# STM32F446 register map
File version: 1.1
CPU: CM4 r1p0, little endian, no MPU, no FPU, 4 interrupt priority bits
Registers are 32-bit, read-write, reset 0x0 unless marked. A register's access mark holds for its fields unless they carry their own. Offsets are from the block's base; [hi:lo] are bit positions; {n}, {i} and the like mark numbered series; 'fields as' and 'values as' point back to an identical list.

## OTG_FS_GLOBAL — USB on the go full speed
Base 0x50000000
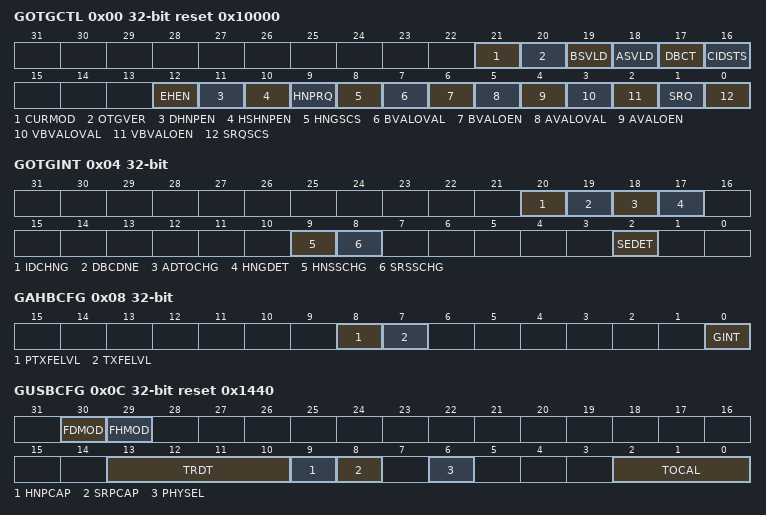
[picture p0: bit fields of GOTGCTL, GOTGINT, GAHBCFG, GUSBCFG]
0x00 GOTGCTL access per field reset 0x10000 — OTG control and status register (OTG_GOTGCTL)
  [21] CURMOD ro — Current mode of operation
  [20] OTGVER rw — OTG version
  [19] BSVLD ro — B-session valid
  [18] ASVLD ro — A-session valid
  [17] DBCT ro — Long/short debounce time
  [16] CIDSTS ro — Connector ID status
  [12] EHEN rw — Embedded host enable
  [11] DHNPEN rw — Device HNP enabled
  [10] HSHNPEN rw — Host set HNP enable
  [9] HNPRQ rw — HNP request
  [8] HNGSCS ro — Host negotiation success
  [7] BVALOVAL rw — B-peripheral session valid override value
  [6] BVALOEN rw — B-peripheral session valid override enable
  [5] AVALOVAL rw — A-peripheral session valid override value
  [4] AVALOEN rw — A-peripheral session valid override enable
  [3] VBVALOVAL rw — Vbus valid override value
  [2] VBVALOEN rw — Vbus valid override enable
  [1] SRQ rw — Session request
  [0] SRQSCS ro — Session request success
0x04 GOTGINT — OTG interrupt register (OTG_GOTGINT)
  [20] IDCHNG
  [19] DBCDNE — Debounce done
  [18] ADTOCHG — A-device timeout change
  [17] HNGDET — Host negotiation detected
  [9] HNSSCHG — Host negotiation success status change
  [8] SRSSCHG — Session request success status change
  [2] SEDET — Session end detected
0x08 GAHBCFG — OTG AHB configuration register (OTG_GAHBCFG)
  [8] PTXFELVL — Periodic TxFIFO empty level
  [7] TXFELVL — TxFIFO empty level
  [0] GINT — Global interrupt mask
0x0C GUSBCFG access per field reset 0x1440 — OTG USB configuration register (OTG_GUSBCFG)
  [30] FDMOD rw — Force device mode
  [29] FHMOD rw — Force host mode
  [13:10] TRDT rw — USB turnaround time
  [9] HNPCAP rw — HNP-capable
  [8] SRPCAP rw — SRP-capable
  [6] PHYSEL ro — Full Speed serial transceiver select
  [2:0] TOCAL rw — FS timeout calibration
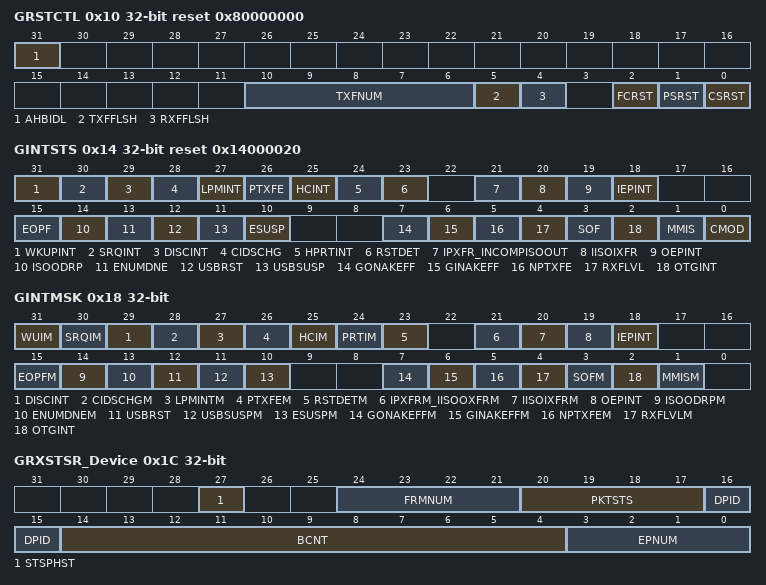
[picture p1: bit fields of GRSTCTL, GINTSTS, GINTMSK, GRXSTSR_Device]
0x10 GRSTCTL access per field reset 0x80000000 — OTG reset register (OTG_GRSTCTL)
  [31] AHBIDL ro — AHB master idle
  [10:6] TXFNUM rw — TxFIFO number
  [5] TXFFLSH rw — TxFIFO flush
  [4] RXFFLSH rw — RxFIFO flush
  [2] FCRST rw — Host frame counter reset
  [1] PSRST rw — Partial soft reset
  [0] CSRST rw — Core soft reset
0x14 GINTSTS access per field reset 0x14000020 — OTG core interrupt register (OTG_GINTSTS)
  [31] WKUPINT rw — Resume/remote wakeup detected interrupt
  [30] SRQINT rw — Session request/new session detected interrupt
  [29] DISCINT rw — Disconnect detected interrupt
  [28] CIDSCHG rw — Connector ID status change
  [27] LPMINT rw — LPM interrupt
  [26] PTXFE ro — Periodic TxFIFO empty
  [25] HCINT ro — Host channels interrupt
  [24] HPRTINT ro — Host port interrupt
  [23] RSTDET rw — Reset detected interrupt
  [21] IPXFR_INCOMPISOOUT rw — Incomplete periodic transfer(Host mode)/Incomplete isochronous OUT transfer(Device mode)
  [20] IISOIXFR rw — Incomplete isochronous IN transfer
  [19] OEPINT ro — OUT endpoint interrupt
  [18] IEPINT ro — IN endpoint interrupt
  [15] EOPF rw — End of periodic frame interrupt
  [14] ISOODRP rw — Isochronous OUT packet dropped interrupt
  [13] ENUMDNE rw — Enumeration done
  [12] USBRST rw — USB reset
  [11] USBSUSP rw — USB suspend
  [10] ESUSP rw — Early suspend
  [7] GONAKEFF ro — Global OUT NAK effective
  [6] GINAKEFF ro — Global IN non-periodic NAK effective
  [5] NPTXFE ro — Non-periodic TxFIFO empty
  [4] RXFLVL ro — RxFIFO non-empty
  [3] SOF rw — Start of frame
  [2] OTGINT ro — OTG interrupt
  [1] MMIS rw — Mode mismatch interrupt
  [0] CMOD ro — Current mode of operation
0x18 GINTMSK — OTG interrupt mask register (OTG_GINTMSK)
  [31] WUIM — Resume/remote wakeup detected interrupt mask
  [30] SRQIM — Session request/new session detected interrupt mask
  [29] DISCINT — Disconnect detected interrupt mask
  [28] CIDSCHGM — Connector ID status change mask
  [27] LPMINTM — LPM interrupt mask
  [26] PTXFEM — Periodic TxFIFO empty mask
  [25] HCIM — Host channels interrupt mask
  [24] PRTIM — Host port interrupt mask
  [23] RSTDETM — Reset detected interrupt mask
  [21] IPXFRM_IISOOXFRM — Incomplete periodic transfer mask(Host mode)/Incomplete isochronous OUT transfer mask(Device mode)
  [20] IISOIXFRM — Incomplete isochronous IN transfer mask
  [19] OEPINT — OUT endpoints interrupt mask
  [18] IEPINT — IN endpoints interrupt mask
  [15] EOPFM — End of periodic frame interrupt mask
  [14] ISOODRPM — Isochronous OUT packet dropped interrupt mask
  [13] ENUMDNEM — Enumeration done mask
  [12] USBRST — USB reset mask
  [11] USBSUSPM — USB suspend mask
  [10] ESUSPM — Early suspend mask
  [7] GONAKEFFM — Global OUT NAK effective mask
  [6] GINAKEFFM — Global non-periodic IN NAK effective mask
  [5] NPTXFEM — Non-periodic TxFIFO empty mask
  [4] RXFLVLM — Receive FIFO non-empty mask
  [3] SOFM — Start of frame mask
  [2] OTGINT — OTG interrupt mask
  [1] MMISM — Mode mismatch interrupt mask
0x1C GRXSTSR_Device ro — OTG receive status debug read (device mode)
  [27] STSPHST — Status phase start
  [24:21] FRMNUM — Frame number
  [20:17] PKTSTS — Packet status
  [16:15] DPID — Data PID
  [14:4] BCNT — Byte count
  [3:0] EPNUM — Endpoint number
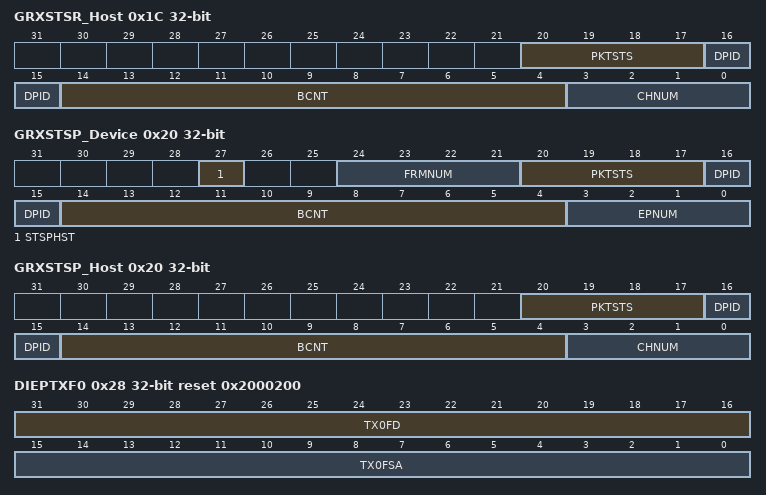
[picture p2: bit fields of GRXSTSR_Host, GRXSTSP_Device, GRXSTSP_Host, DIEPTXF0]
0x1C GRXSTSR_Host ro (alternate view of GRXSTSR_Device) — OTG receive status debug read (host mode)
  [20:17] PKTSTS — Packet status
  [16:15] DPID — Data PID
  [14:4] BCNT — Byte count
  [3:0] CHNUM — Channel number
0x20 GRXSTSP_Device ro — OTG status read and pop (device mode)
  fields as GRXSTSR_Device
0x20 GRXSTSP_Host ro (alternate view of GRXSTSP_Device) — OTG status read and pop (host mode)
  fields as GRXSTSR_Host
0x24 GRXFSIZ reset 0x200 — OTG Receive FIFO size register (OTG_GRXFSIZ)
  [15:0] RXFD — RxFIFO depth
0x28 DIEPTXF0 reset 0x2000200 — Endpoint 0 Transmit FIFO size register (device mode)
  [31:16] TX0FD — Endpoint 0 TxFIFO depth
  [15:0] TX0FSA — Endpoint 0 transmit RAM start address
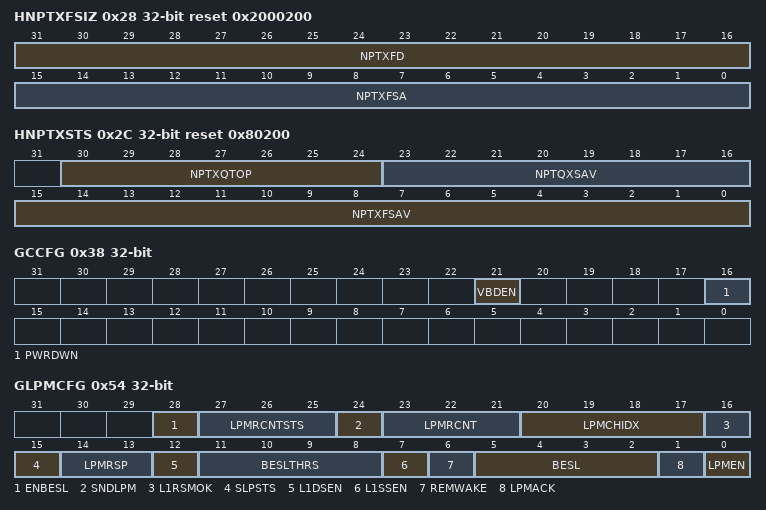
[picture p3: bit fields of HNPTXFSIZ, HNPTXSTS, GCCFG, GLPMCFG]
0x28 HNPTXFSIZ reset 0x2000200 (alternate view of DIEPTXF0) — OTG host non-periodic transmit FIFO size register (host mode)
  [31:16] NPTXFD — Non-periodic TxFIFO depth
  [15:0] NPTXFSA — Non-periodic transmit RAM start address
0x2C HNPTXSTS ro reset 0x80200 — OTG non-periodic transmit FIFO/queue status register (OTG_HNPTXSTS)
  [30:24] NPTXQTOP — Top of the non-periodic transmit request queue
  [23:16] NPTQXSAV — Non-periodic transmit request queue space available
  [15:0] NPTXFSAV — Non-periodic TxFIFO space available
0x38 GCCFG — OTG general core configuration register (OTG_GCCFG)
  [21] VBDEN — USB Vbus detection enable
  [16] PWRDWN — Power down control
0x3C CID reset 0x2000 — OTG core ID register
  [31:0] PRODUCT_ID
0x54 GLPMCFG access per field — OTG core LPM configuration register (OTG_GLPMCFG)
  [28] ENBESL rw — Enable best effort service latency
  [27:25] LPMRCNTSTS ro — LPM retry count status
  [24] SNDLPM rw — Send LPM transaction
  [23:21] LPMRCNT rw — LPM retry count
  [20:17] LPMCHIDX rw — LPM Channel Index
  [16] L1RSMOK ro — Sleep state resume OK
  [15] SLPSTS ro — Port sleep status
  [14:13] LPMRSP ro — LPM response
  [12] L1DSEN rw — L1 deep sleep enable
  [11:8] BESLTHRS rw — BESL threshold
  [7] L1SSEN rw — L1 Shallow Sleep enable
  [6] REMWAKE rw — bRemoteWake value
  [5:2] BESL rw — Best effort service latency
  [1] LPMACK rw — LPM token acknowledge enable
  [0] LPMEN rw — LPM support enable
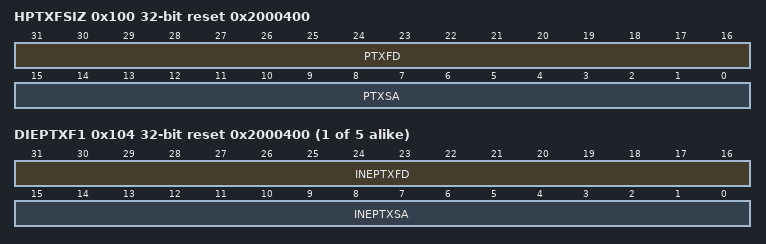
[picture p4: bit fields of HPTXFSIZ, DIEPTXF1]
0x100 HPTXFSIZ reset 0x2000400 — OTG host periodic transmit FIFO size register (OTG_HPTXFSIZ)
  [31:16] PTXFD — Host periodic TxFIFO depth
  [15:0] PTXSA — Host periodic TxFIFO start address
{0x100+4i} DIEPTXF{i} (i=1..5) reset 0x2000400 — OTG device IN endpoint transmit FIFO size register (OTG_DIEPTXFx)
  [31:16] INEPTXFD — IN endpoint TxFIFO depth
  [15:0] INEPTXSA — IN endpoint FIFO transmit RAM start address
